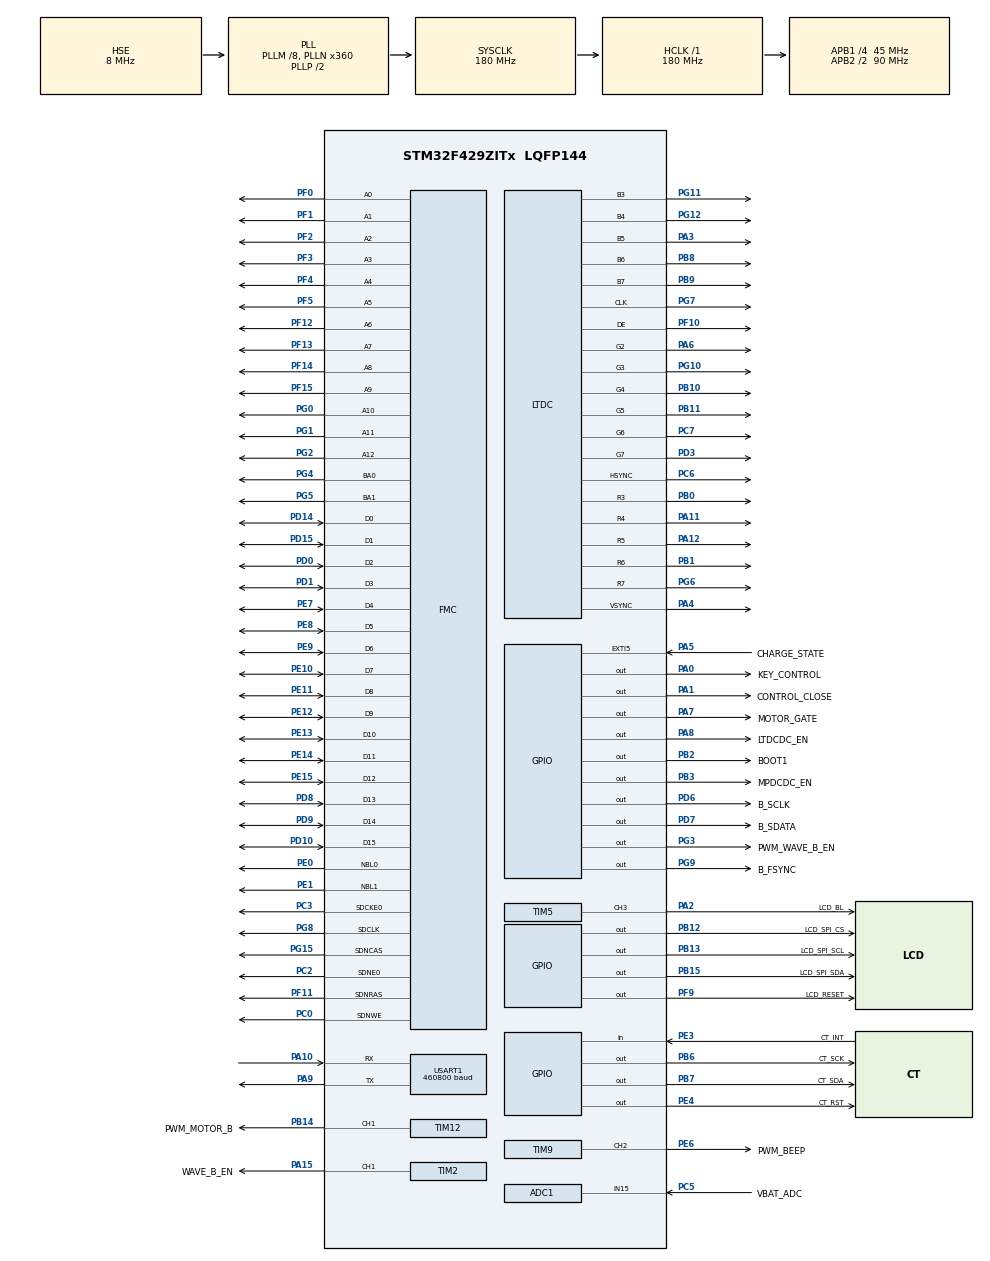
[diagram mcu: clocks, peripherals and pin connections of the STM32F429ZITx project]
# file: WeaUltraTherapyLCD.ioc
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ADC1.Channel-0\#ChannelRegularConversion=ADC_CHANNEL_15
ADC1.NbrOfConversionFlag=1
ADC1.Rank-0\#ChannelRegularConversion=1
ADC1.SamplingTime-0\#ChannelRegularConversion=ADC_SAMPLETIME_3CYCLES
ADC1.master=1
DMA2D.ColorMode=DMA2D_OUTPUT_RGB565
DMA2D.Mode=DMA2D_R2M
Dma.ADC1.0.Direction=DMA_PERIPH_TO_MEMORY
Dma.ADC1.0.FIFOMode=DMA_FIFOMODE_DISABLE
Dma.ADC1.0.Instance=DMA2_Stream0
Dma.ADC1.0.MemDataAlignment=DMA_MDATAALIGN_HALFWORD
Dma.ADC1.0.MemInc=DMA_MINC_ENABLE
Dma.ADC1.0.Mode=DMA_NORMAL
Dma.ADC1.0.PeriphDataAlignment=DMA_PDATAALIGN_HALFWORD
Dma.ADC1.0.PeriphInc=DMA_PINC_DISABLE
Dma.ADC1.0.Priority=DMA_PRIORITY_LOW
Dma.Request0=ADC1
FMC.CASLatency1=FMC_SDRAM_CAS_LATENCY_3
FMC.ColumnBitsNumber1=FMC_SDRAM_COLUMN_BITS_NUM_9
FMC.ExitSelfRefreshDelay1=7
FMC.LoadToActiveDelay1=2
FMC.RCDDelay1=2
FMC.RPDelay1=2
FMC.RPDelay2=2
FMC.ReadBurst1=FMC_SDRAM_RBURST_ENABLE
FMC.ReadBurst2=FMC_SDRAM_RBURST_ENABLE
FMC.ReadPipeDelay1=FMC_SDRAM_RPIPE_DELAY_1
FMC.ReadPipeDelay2=FMC_SDRAM_RPIPE_DELAY_1
FMC.RowCycleDelay1=6
FMC.RowCycleDelay2=6
FMC.SDClockPeriod1=FMC_SDRAM_CLOCK_PERIOD_2
FMC.SDClockPeriod2=FMC_SDRAM_CLOCK_PERIOD_2
FMC.SelfRefreshTime1=6
FMC.WriteRecoveryTime1=4
FREERTOS.Tasks01=ScreenRGB,40,1024,ScreenRGBTask,Default,NULL,Static,ScreenRGBBuffer,ScreenRGBControlBlock;UltraApp,8,256,UltraAppTask,Default,NULL,Static,UltraAppBuffer,UltraAppControlBlock;OtherFunc,8,128,OtherFuncTask,Default,NULL,Static,OtherFuncBuffer,OtherFuncControlBlock
IWDG.Prescaler=IWDG_PRESCALER_32
IWDG.Reload=1000
LTDC.ActiveH=800
LTDC.ActiveW=480
LTDC.Alpha_L0=255
LTDC.BlendingFactor1_L0=LTDC_BLENDING_FACTOR1_PAxCA
LTDC.BlendingFactor2_L0=LTDC_BLENDING_FACTOR2_PAxCA
LTDC.DEPolarity=LTDC_DEPOLARITY_AL
LTDC.FBStartAdress_L0=0xC0000000
LTDC.HBP=30
LTDC.HFP=10
LTDC.HSPolarity=LTDC_HSPOLARITY_AL
LTDC.HSync=2
LTDC.ImageHeight_L0=800
LTDC.ImageWidth_L0=480
LTDC.Layers=0
LTDC.PCPolarity=LTDC_PCPOLARITY_IIPC
LTDC.PixelFormat_L0=LTDC_PIXEL_FORMAT_RGB565
LTDC.VBP=20
LTDC.VFP=80
LTDC.VSPolarity=LTDC_VSPOLARITY_AL
LTDC.VSync=2
LTDC.WindowX1_L0=480
LTDC.WindowY1_L0=800
Mcu.Family=STM32F4
Mcu.Name=STM32F429ZITx
Mcu.Package=LQFP144
NVIC.DMA2_Stream0_IRQn=true\:5\:0\:false\:false\:true\:true\:false\:true\:true
NVIC.EXTI9_5_IRQn=true\:5\:0\:false\:false\:true\:true\:true\:true\:true
NVIC.PriorityGroup=NVIC_PRIORITYGROUP_4
NVIC.TIM2_IRQn=true\:5\:0\:false\:false\:true\:false\:true\:true\:true
NVIC.TIM3_IRQn=true\:5\:0\:false\:false\:true\:true\:true\:true\:true
NVIC.TIM8_BRK_TIM12_IRQn=true\:5\:0\:true\:false\:true\:false\:true\:true\:true
NVIC.TIM8_TRG_COM_TIM14_IRQn=true\:15\:0\:false\:false\:true\:false\:false\:true\:true
NVIC.TIM8_UP_TIM13_IRQn=true\:5\:0\:false\:false\:true\:true\:true\:true\:true
NVIC.TimeBase=TIM8_TRG_COM_TIM14_IRQn
NVIC.TimeBaseIP=TIM14
PA0/WKUP.GPIO_Label=KEY_CONTROL
PA0/WKUP.Signal=GPIO_Output
PA1.GPIO_Label=CONTROL_CLOSE
PA1.Signal=GPIO_Output
PA10.Mode=Asynchronous
PA10.Signal=USART1_RX
PA11.GPIO_Speed=GPIO_SPEED_FREQ_VERY_HIGH
PA11.Mode=RGB565
PA11.Signal=LTDC_R4
PA12.GPIO_Speed=GPIO_SPEED_FREQ_VERY_HIGH
PA12.Mode=RGB565
PA12.Signal=LTDC_R5
PA13.Mode=Serial_Wire
PA13.Signal=SYS_JTMS-SWDIO
PA14.Mode=Serial_Wire
PA14.Signal=SYS_JTCK-SWCLK
PA15.GPIO_Label=WAVE_B_EN
PA15.Signal=S_TIM2_CH1_ETR
PA2.GPIO_Label=LCD_BL
PA2.Signal=S_TIM5_CH3
PA3.GPIO_Speed=GPIO_SPEED_FREQ_VERY_HIGH
PA3.Mode=RGB565
PA3.Signal=LTDC_B5
PA4.GPIO_Speed=GPIO_SPEED_FREQ_VERY_HIGH
PA4.Mode=RGB565
PA4.Signal=LTDC_VSYNC
PA5.GPIO_Label=CHARGE_STATE
PA5.GPIO_ModeDefaultEXTI=GPIO_MODE_IT_RISING_FALLING
PA5.GPIO_PuPd=GPIO_PULLUP
PA5.Signal=GPXTI5
PA6.GPIO_Speed=GPIO_SPEED_FREQ_VERY_HIGH
PA6.Mode=RGB565
PA6.Signal=LTDC_G2
PA7.GPIO_Label=MOTOR_GATE
PA7.GPIO_ModeDefaultOutputPP=GPIO_MODE_OUTPUT_PP
PA7.GPIO_PuPd=GPIO_PULLUP
PA7.GPIO_Speed=GPIO_SPEED_FREQ_HIGH
PA7.PinState=GPIO_PIN_RESET
PA7.Signal=GPIO_Output
PA8.GPIO_Label=LTDCDC_EN
PA8.Signal=GPIO_Output
PA9.Mode=Asynchronous
PA9.Signal=USART1_TX
PB0.GPIO_Speed=GPIO_SPEED_FREQ_VERY_HIGH
PB0.Mode=RGB565
PB0.Signal=LTDC_R3
PB1.GPIO_Speed=GPIO_SPEED_FREQ_VERY_HIGH
PB1.Mode=RGB565
PB1.Signal=LTDC_R6
PB10.GPIO_Speed=GPIO_SPEED_FREQ_VERY_HIGH
PB10.Mode=RGB565
PB10.Signal=LTDC_G4
PB11.GPIO_Speed=GPIO_SPEED_FREQ_VERY_HIGH
PB11.Mode=RGB565
PB11.Signal=LTDC_G5
PB12.GPIO_Label=LCD_SPI_CS
PB12.GPIO_PuPd=GPIO_PULLUP
PB12.GPIO_Speed=GPIO_SPEED_FREQ_VERY_HIGH
PB12.PinState=GPIO_PIN_RESET
PB12.Signal=GPIO_Output
PB13.GPIO_Label=LCD_SPI_SCL
PB13.GPIO_PuPd=GPIO_PULLUP
PB13.GPIO_Speed=GPIO_SPEED_FREQ_VERY_HIGH
PB13.Signal=GPIO_Output
PB14.GPIO_Label=PWM_MOTOR_B
PB14.Signal=S_TIM12_CH1
PB15.GPIO_Label=LCD_SPI_SDA
PB15.GPIO_PuPd=GPIO_PULLUP
PB15.GPIO_Speed=GPIO_SPEED_FREQ_VERY_HIGH
PB15.Signal=GPIO_Output
PB2/BOOT1.GPIO_Label=BOOT1
PB2/BOOT1.GPIO_PuPd=GPIO_PULLDOWN
PB2/BOOT1.Signal=GPIO_Output
PB3.GPIO_Label=MPDCDC_EN
PB3.Signal=GPIO_Output
PB6.GPIO_Label=CT_SCK
PB6.GPIO_ModeDefaultOutputPP=GPIO_MODE_OUTPUT_OD
PB6.GPIO_PuPd=GPIO_PULLUP
PB6.GPIO_Speed=GPIO_SPEED_FREQ_VERY_HIGH
PB6.Signal=GPIO_Output
PB7.GPIO_Label=CT_SDA
PB7.GPIO_ModeDefaultOutputPP=GPIO_MODE_OUTPUT_OD
PB7.GPIO_PuPd=GPIO_PULLUP
PB7.GPIO_Speed=GPIO_SPEED_FREQ_VERY_HIGH
PB7.Signal=GPIO_Output
PB8.GPIO_Speed=GPIO_SPEED_FREQ_VERY_HIGH
PB8.Mode=RGB565
PB8.Signal=LTDC_B6
PB9.GPIO_Speed=GPIO_SPEED_FREQ_VERY_HIGH
PB9.Mode=RGB565
PB9.Signal=LTDC_B7
PC0.Signal=FMC_SDNWE
PC2.Mode=SdramChipSelect1_1
PC2.Signal=FMC_SDNE0
PC3.Mode=SdramChipSelect1_1
PC3.Signal=FMC_SDCKE0
PC5.GPIO_Label=VBAT_ADC
PC5.Signal=ADCx_IN15
PC6.GPIO_Speed=GPIO_SPEED_FREQ_VERY_HIGH
PC6.Mode=RGB565
PC6.Signal=LTDC_HSYNC
PC7.GPIO_Speed=GPIO_SPEED_FREQ_VERY_HIGH
PC7.Mode=RGB565
PC7.Signal=LTDC_G6
PD0.Signal=FMC_D2_DA2
PD1.Signal=FMC_D3_DA3
PD10.Signal=FMC_D15_DA15
PD14.Signal=FMC_D0_DA0
PD15.Signal=FMC_D1_DA1
PD3.GPIO_Speed=GPIO_SPEED_FREQ_VERY_HIGH
PD3.Mode=RGB565
PD3.Signal=LTDC_G7
PD6.GPIO_Label=B_SCLK
PD6.GPIO_Speed=GPIO_SPEED_FREQ_VERY_HIGH
PD6.Signal=GPIO_Output
PD7.GPIO_Label=B_SDATA
PD7.GPIO_Speed=GPIO_SPEED_FREQ_VERY_HIGH
PD7.Signal=GPIO_Output
PD8.Signal=FMC_D13_DA13
PD9.Signal=FMC_D14_DA14
PE0.Signal=FMC_NBL0
PE1.Signal=FMC_NBL1
PE10.Signal=FMC_D7_DA7
PE11.Signal=FMC_D8_DA8
PE12.Signal=FMC_D9_DA9
PE13.Signal=FMC_D10_DA10
PE14.Signal=FMC_D11_DA11
PE15.Signal=FMC_D12_DA12
PE3.GPIO_Label=CT_INT
PE3.GPIO_Mode=GPIO_MODE_INPUT
PE3.GPIO_PuPd=GPIO_PULLUP
PE3.Signal=GPIO_Input
PE4.GPIO_Label=CT_RST
PE4.Signal=GPIO_Output
PE6.GPIO_Label=PWM_BEEP
PE6.Signal=S_TIM9_CH2
PE7.Signal=FMC_D4_DA4
PE8.Signal=FMC_D5_DA5
PE9.Signal=FMC_D6_DA6
PF0.Signal=FMC_A0
PF1.Signal=FMC_A1
PF10.GPIO_Speed=GPIO_SPEED_FREQ_VERY_HIGH
PF10.Mode=RGB565
PF10.Signal=LTDC_DE
PF11.Signal=FMC_SDNRAS
PF12.Signal=FMC_A6
PF13.Signal=FMC_A7
PF14.Signal=FMC_A8
PF15.Signal=FMC_A9
PF2.Signal=FMC_A2
PF3.Signal=FMC_A3
PF4.Signal=FMC_A4
PF5.Signal=FMC_A5
PF9.GPIO_Label=LCD_RESET
PF9.Signal=GPIO_Output
PG0.Signal=FMC_A10
PG1.Signal=FMC_A11
PG10.GPIO_Speed=GPIO_SPEED_FREQ_VERY_HIGH
PG10.Mode=RGB565
PG10.Signal=LTDC_G3
PG11.GPIO_Speed=GPIO_SPEED_FREQ_VERY_HIGH
PG11.Mode=RGB565
PG11.Signal=LTDC_B3
PG12.GPIO_Speed=GPIO_SPEED_FREQ_VERY_HIGH
PG12.Mode=RGB565
PG12.Signal=LTDC_B4
PG15.Signal=FMC_SDNCAS
PG2.Signal=FMC_A12
PG3.GPIO_Label=PWM_WAVE_B_EN
PG3.Signal=GPIO_Output
PG4.Signal=FMC_A14_BA0
PG5.Signal=FMC_A15_BA1
PG6.GPIO_Speed=GPIO_SPEED_FREQ_VERY_HIGH
PG6.Mode=RGB565
PG6.Signal=LTDC_R7
PG7.GPIO_Speed=GPIO_SPEED_FREQ_VERY_HIGH
PG7.Mode=RGB565
PG7.Signal=LTDC_CLK
PG8.Signal=FMC_SDCLK
PG9.GPIO_Label=B_FSYNC
PG9.GPIO_Speed=GPIO_SPEED_FREQ_LOW
PG9.Signal=GPIO_Output
PH0/OSC_IN.Mode=HSE-External-Oscillator
PH0/OSC_IN.Signal=RCC_OSC_IN
PH1/OSC_OUT.Mode=HSE-External-Oscillator
PH1/OSC_OUT.Signal=RCC_OSC_OUT
ProjectManager.HeapSize=0x200
ProjectManager.StackSize=0x400
ProjectManager.TargetToolchain=MDK-ARM V5.32
RCC.48MHZClocksFreq_Value=90000000
RCC.AHBFreq_Value=180000000
RCC.APB1CLKDivider=RCC_HCLK_DIV4
RCC.APB1Freq_Value=45000000
RCC.APB1TimFreq_Value=90000000
RCC.APB2CLKDivider=RCC_HCLK_DIV2
RCC.APB2Freq_Value=90000000
RCC.APB2TimFreq_Value=180000000
RCC.CortexFreq_Value=180000000
RCC.HCLKFreq_Value=180000000
RCC.HSE_VALUE=8000000
RCC.HSI_VALUE=16000000
RCC.LSE_VALUE=32768
RCC.PLLM=8
RCC.PLLN=360
RCC.PLLSAIDivR=RCC_PLLSAIDIVR_4
RCC.PLLSAIN=336
RCC.PLLSAIR=3
RCC.PLLSourceVirtual=RCC_PLLSOURCE_HSE
RCC.SYSCLKFreq_VALUE=180000000
RCC.SYSCLKSource=RCC_SYSCLKSOURCE_PLLCLK
RCC.VCOOutputFreq_Value=360000000
SH.ADCx_IN15.0=ADC1_IN15,IN15
SH.FMC_A0.0=FMC_A0,13b-sda1
SH.FMC_A1.0=FMC_A1,13b-sda1
SH.FMC_A10.0=FMC_A10,13b-sda1
SH.FMC_A11.0=FMC_A11,13b-sda1
SH.FMC_A12.0=FMC_A12,13b-sda1
SH.FMC_A14_BA0.0=FMC_BA0,FourSdramBanks1
SH.FMC_A15_BA1.0=FMC_BA1,FourSdramBanks1
SH.FMC_A2.0=FMC_A2,13b-sda1
SH.FMC_A3.0=FMC_A3,13b-sda1
SH.FMC_A4.0=FMC_A4,13b-sda1
SH.FMC_A5.0=FMC_A5,13b-sda1
SH.FMC_A6.0=FMC_A6,13b-sda1
SH.FMC_A7.0=FMC_A7,13b-sda1
SH.FMC_A8.0=FMC_A8,13b-sda1
SH.FMC_A9.0=FMC_A9,13b-sda1
SH.FMC_D0_DA0.0=FMC_D0,sd-16b-d1
SH.FMC_D10_DA10.0=FMC_D10,sd-16b-d1
SH.FMC_D11_DA11.0=FMC_D11,sd-16b-d1
SH.FMC_D12_DA12.0=FMC_D12,sd-16b-d1
SH.FMC_D13_DA13.0=FMC_D13,sd-16b-d1
SH.FMC_D14_DA14.0=FMC_D14,sd-16b-d1
SH.FMC_D15_DA15.0=FMC_D15,sd-16b-d1
SH.FMC_D1_DA1.0=FMC_D1,sd-16b-d1
SH.FMC_D2_DA2.0=FMC_D2,sd-16b-d1
SH.FMC_D3_DA3.0=FMC_D3,sd-16b-d1
SH.FMC_D4_DA4.0=FMC_D4,sd-16b-d1
SH.FMC_D5_DA5.0=FMC_D5,sd-16b-d1
SH.FMC_D6_DA6.0=FMC_D6,sd-16b-d1
SH.FMC_D7_DA7.0=FMC_D7,sd-16b-d1
SH.FMC_D8_DA8.0=FMC_D8,sd-16b-d1
SH.FMC_D9_DA9.0=FMC_D9,sd-16b-d1
SH.FMC_NBL0.0=FMC_NBL0,Sd2ByteEnable1
SH.FMC_NBL1.0=FMC_NBL1,Sd2ByteEnable1
SH.FMC_SDCLK.0=FMC_SDCLK,13b-sda1
SH.FMC_SDNCAS.0=FMC_SDNCAS,13b-sda1
SH.FMC_SDNRAS.0=FMC_SDNRAS,13b-sda1
SH.FMC_SDNWE.0=FMC_SDNWE,13b-sda1
SH.S_TIM12_CH1.0=TIM12_CH1,PWM Generation1 CH1
SH.S_TIM2_CH1_ETR.0=TIM2_CH1,PWM Generation1 CH1
SH.S_TIM5_CH3.0=TIM5_CH3,PWM Generation3 CH3
SH.S_TIM9_CH2.0=TIM9_CH2,PWM Generation2 CH2
TIM12.Channel-PWM\ Generation1\ CH1=TIM_CHANNEL_1
TIM12.Period=4256-1
TIM12.Prescaler=90-1
TIM2.Channel-PWM\ Generation1\ CH1=TIM_CHANNEL_1
TIM2.Period=2500
TIM2.Prescaler=90-1
TIM3.Period=100-1
TIM3.Prescaler=90-1
TIM5.Channel-PWM\ Generation3\ CH3=TIM_CHANNEL_3
TIM5.Period=4255
TIM5.Prescaler=90-1
TIM8.Period=1000
TIM8.Prescaler=180-1
TIM9.Channel-PWM\ Generation2\ CH2=TIM_CHANNEL_2
TIM9.Period=400
TIM9.Prescaler=180-1
USART1.BaudRate=460800
USART1.VirtualMode=VM_ASYNC
VP_DMA2D_VS_DMA2D.Mode=DMA2D_Activate
VP_FREERTOS_VS_CMSIS_V2.Mode=CMSIS_V2
VP_IWDG_VS_IWDG.Mode=IWDG_Activate
VP_SYS_VS_tim14.Mode=TIM14
VP_TIM12_VS_ClockSourceINT.Mode=Internal
VP_TIM2_VS_ClockSourceINT.Mode=Internal
VP_TIM3_VS_ClockSourceINT.Mode=Internal
VP_TIM5_VS_ClockSourceINT.Mode=Internal
VP_TIM8_VS_ClockSourceINT.Mode=Internal
VP_TIM9_VS_ClockSourceINT.Mode=Internal
board=custom

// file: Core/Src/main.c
/* USER CODE BEGIN Header */
/**
  ******************************************************************************
  * @file           : main.c
  * @brief          : Main program body
  ******************************************************************************
  * @attention
  *
  * Copyright (c) 2024 STMicroelectronics.
  * All rights reserved.
  *
  * This software is licensed under terms that can be found in the LICENSE file
  * in the root directory of this software component.
  * If no LICENSE file comes with this software, it is provided AS-IS.
  *
  ******************************************************************************
  */
/* USER CODE END Header */
#include "main.h"
#include "cmsis_os.h"
#include "adc.h"
#include "dma.h"
#include "dma2d.h"
#include "iwdg.h"
#include "ltdc.h"
#include "tim.h"
#include "usart.h"
#include "gpio.h"
#include "fmc.h"

/* USER CODE BEGIN Includes */
#include "dev_malloc.h"
#include "lv_port_disp_template.h"
#include "lv_port_indev_template.h"
#include "dev_st7701.h"
#include "dev_app.h"
#include "lv_mainstart.h"
/* USER CODE END Includes */

/* USER CODE BEGIN PV */
uint32_t ScreenTime = 0;										//屝幕主界面数杮刷新时�?
uint32_t StandyTime = 0;										//待机时间
uint32_t ChargeRecvTime = 0;								//充电接收时间
uint32_t BatteryTime = 0;										//主界面电池刷新时�?
uint32_t BackLedTime = 0;			  						//背光启动时间
uint32_t PowerOnTime = 0;										//正式�?机时�?
uint32_t Charge_Time = 0;										//充电时长
uint32_t ShuntDownCount = 0;
uint32_t MotorTime = 0;
uint8_t CompleteFlg = 0;										//启动成功
uint32_t UltraWorkTim = 0;
uint32_t UnlockCount = 0;
uint32_t VibraFeedBackTime = 0;												//震动反馈时间
uint32_t DisplayTime = 0;
uint32_t BeatTime = 0;
uint32_t HintTime = 0;
uint8_t LongPressFlg = 0;
uint32_t LongPressTime = 0;
/* USER CODE END PV */

void SystemClock_Config(void);
void MX_FREERTOS_Init(void);

int main(void)
{

  /* MCU Configuration--------------------------------------------------------*/

  /* Reset of all peripherals, Initializes the Flash interface and the Systick. */
  HAL_Init();

  /* Configure the system clock */
  SystemClock_Config();

  /* Initialize all configured peripherals */
  MX_GPIO_Init();
  MX_DMA_Init();
  MX_DMA2D_Init();
  MX_FMC_Init();
  MX_TIM2_Init();
  MX_LTDC_Init();
  MX_ADC1_Init();
  MX_TIM5_Init();
  MX_TIM9_Init();
  MX_TIM3_Init();
  MX_TIM12_Init();
  MX_TIM8_Init();
  MX_USART1_UART_Init();
  //MX_IWDG_Init();
  /* USER CODE BEGIN 2 */
	UltraParam_Init();
	st7701_init();
	my_mem_init(SRAMIN);                        				/* 初始化内部SRAM内存�? */
	my_mem_init(SRAMEX);                        				/* 初始化外部SRAM内存�? */
	lv_init();                                          /* lvgl系统初始�? */
	lv_port_disp_init();                                /* lvgl显示接口初始�?,放在lv_init()的后�?*/
	lv_port_indev_init();                               /* lvgl输入接口初始�?,放在lv_init()的后�?*/

	HAL_TIM_Base_Start(&htim2);
	HAL_TIM_Base_Start(&htim5);
	HAL_TIM_Base_Start(&htim9);
	HAL_TIM_Base_Start(&htim12);
	HAL_TIM_Base_Start_IT(&htim3);
	HAL_TIM_Base_Start_IT(&htim8);

  HAL_TIM_PWM_Start(&htim2,TIM_CHANNEL_1);
	HAL_TIM_PWM_Start(&htim5,TIM_CHANNEL_3);
	HAL_TIM_PWM_Start(&htim9,TIM_CHANNEL_2);
	HAL_TIM_PWM_Start(&htim12,TIM_CHANNEL_1);
  /* USER CODE END 2 */

  /* Init scheduler */
  osKernelInitialize();

  /* Call init function for freertos objects (in cmsis_os2.c) */
  MX_FREERTOS_Init();

  /* Start scheduler */
  osKernelStart();

  /* We should never get here as control is now taken by the scheduler */

  /* Infinite loop */
  while (1)
  {

  }
}

void SystemClock_Config(void)
{
  RCC_OscInitTypeDef RCC_OscInitStruct = {0};
  RCC_ClkInitTypeDef RCC_ClkInitStruct = {0};

  /** Configure the main internal regulator output voltage
  */
  __HAL_RCC_PWR_CLK_ENABLE();
  __HAL_PWR_VOLTAGESCALING_CONFIG(PWR_REGULATOR_VOLTAGE_SCALE1);

  /** Initializes the RCC Oscillators according to the specified parameters
  * in the RCC_OscInitTypeDef structure.
  */
  RCC_OscInitStruct.OscillatorType = RCC_OSCILLATORTYPE_LSI|RCC_OSCILLATORTYPE_HSE;
  RCC_OscInitStruct.HSEState = RCC_HSE_ON;
  RCC_OscInitStruct.LSIState = RCC_LSI_ON;
  RCC_OscInitStruct.PLL.PLLState = RCC_PLL_ON;
  RCC_OscInitStruct.PLL.PLLSource = RCC_PLLSOURCE_HSE;
  RCC_OscInitStruct.PLL.PLLM = 8;
  RCC_OscInitStruct.PLL.PLLN = 360;
  RCC_OscInitStruct.PLL.PLLP = RCC_PLLP_DIV2;
  RCC_OscInitStruct.PLL.PLLQ = 4;
  if (HAL_RCC_OscConfig(&RCC_OscInitStruct) != HAL_OK)
  {
    Error_Handler();
  }

  /** Activate the Over-Drive mode
  */
  if (HAL_PWREx_EnableOverDrive() != HAL_OK)
  {
    Error_Handler();
  }

  /** Initializes the CPU, AHB and APB buses clocks
  */
  RCC_ClkInitStruct.ClockType = RCC_CLOCKTYPE_HCLK|RCC_CLOCKTYPE_SYSCLK
                              |RCC_CLOCKTYPE_PCLK1|RCC_CLOCKTYPE_PCLK2;
  RCC_ClkInitStruct.SYSCLKSource = RCC_SYSCLKSOURCE_PLLCLK;
  RCC_ClkInitStruct.AHBCLKDivider = RCC_SYSCLK_DIV1;
  RCC_ClkInitStruct.APB1CLKDivider = RCC_HCLK_DIV4;
  RCC_ClkInitStruct.APB2CLKDivider = RCC_HCLK_DIV2;

  if (HAL_RCC_ClockConfig(&RCC_ClkInitStruct, FLASH_LATENCY_5) != HAL_OK)
  {
    Error_Handler();
  }
}

void HAL_TIM_PeriodElapsedCallback(TIM_HandleTypeDef *htim)
{
  /* USER CODE BEGIN Callback 0 */
	static uint8_t BeepTime = 0;

  /* USER CODE END Callback 0 */
  if (htim->Instance == TIM14) {
    HAL_IncTick();
  }
  /* USER CODE BEGIN Callback 1 */
	//1ms周期
	if(htim->Instance == TIM8)
	{
		  BackLedTime++;
		  StandyTime++;
			ScreenTime++;
		  BatteryTime++;
			PowerOnTime++;
			MotorTime++;
			ShuntDownCount++;
			UltraWorkTim++;
			UnlockCount++;
      VibraFeedBackTime++;
      BeatTime++;

			if((ScreenState == STOP) || (ScreenState == COMPLETE))
			{
					HintTime++;
			}else
			{
				  HintTime = 0;
			}

      if (DisplayFlg == 1)
      {
         DisplayTime++;
      }

			if(PowerOnTime > 1500)
			{
					CompleteFlg = 1;
			}

			if(LongPressFlg == 1)
			{
				LongPressTime++;
			}else
			{
				LongPressTime = 0;
			}

			BeepTime++;
			if(BeepTime > 8)
			{
					Beep_MainFunc();
					BeepTime = 0;
			}

			if(DevWorkState == CHARGE_STATE)
			{
				Charge_Time++;
			}
	}

	if(htim->Instance == TIM3)
	{
			ChargeRecvTime++;
	}
  /* USER CODE END Callback 1 */
}

void Error_Handler(void)
{
  __disable_irq();
  while (1)
  {
  }
}

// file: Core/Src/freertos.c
/* USER CODE BEGIN Header */
/**
  ******************************************************************************
  * File Name          : freertos.c
  * Description        : Code for freertos applications
  ******************************************************************************
  * @attention
  *
  * Copyright (c) 2024 STMicroelectronics.
  * All rights reserved.
  *
  * This software is licensed under terms that can be found in the LICENSE file
  * in the root directory of this software component.
  * If no LICENSE file comes with this software, it is provided AS-IS.
  *
  ******************************************************************************
  */
/* USER CODE END Header */

#include "FreeRTOS.h"
#include "task.h"
#include "main.h"
#include "cmsis_os.h"

/* USER CODE BEGIN Includes */
#include "lv_mainstart.h"
#include "lvgl.h"
#include "dev_gt911.h"
#include "dev_ltdc.h"
#include "dev_beep.h"
#include "custom.h"
#include "tim.h"
#include "dev_app.h"
/* USER CODE END Includes */

typedef StaticTask_t osStaticThreadDef_t;

/* USER CODE BEGIN Variables */
extern IWDG_HandleTypeDef hiwdg;
extern uint16_t RefreshCount;
extern uint32_t BackLedTime;
static uint8_t StartFlg = 0;

/* USER CODE END Variables */
/* Definitions for ScreenRGB */
osThreadId_t ScreenRGBHandle;
uint32_t ScreenRGBBuffer[ 1024 ];
osStaticThreadDef_t ScreenRGBControlBlock;
const osThreadAttr_t ScreenRGB_attributes = {
  .name = "ScreenRGB",
  .cb_mem = &ScreenRGBControlBlock,
  .cb_size = sizeof(ScreenRGBControlBlock),
  .stack_mem = &ScreenRGBBuffer[0],
  .stack_size = sizeof(ScreenRGBBuffer),
  .priority = (osPriority_t) osPriorityHigh,
};
/* Definitions for UltraApp */
osThreadId_t UltraAppHandle;
uint32_t UltraAppBuffer[ 256 ];
osStaticThreadDef_t UltraAppControlBlock;
const osThreadAttr_t UltraApp_attributes = {
  .name = "UltraApp",
  .cb_mem = &UltraAppControlBlock,
  .cb_size = sizeof(UltraAppControlBlock),
  .stack_mem = &UltraAppBuffer[0],
  .stack_size = sizeof(UltraAppBuffer),
  .priority = (osPriority_t) osPriorityLow,
};
/* Definitions for OtherFunc */
osThreadId_t OtherFuncHandle;
uint32_t OtherFuncBuffer[ 128 ];
osStaticThreadDef_t OtherFuncControlBlock;
const osThreadAttr_t OtherFunc_attributes = {
  .name = "OtherFunc",
  .cb_mem = &OtherFuncControlBlock,
  .cb_size = sizeof(OtherFuncControlBlock),
  .stack_mem = &OtherFuncBuffer[0],
  .stack_size = sizeof(OtherFuncBuffer),
  .priority = (osPriority_t) osPriorityLow,
};

void ScreenRGBTask(void *argument);
void UltraAppTask(void *argument);
void OtherFuncTask(void *argument);

void MX_FREERTOS_Init(void); /* (MISRA C 2004 rule 8.1) */

void MX_FREERTOS_Init(void) {

  /* Create the thread(s) */
  /* creation of ScreenRGB */
  ScreenRGBHandle = osThreadNew(ScreenRGBTask, NULL, &ScreenRGB_attributes);

  /* creation of UltraApp */
  UltraAppHandle = osThreadNew(UltraAppTask, NULL, &UltraApp_attributes);

  /* creation of OtherFunc */
  OtherFuncHandle = osThreadNew(OtherFuncTask, NULL, &OtherFunc_attributes);

}

void ScreenRGBTask(void *argument)
{
  /* USER CODE BEGIN ScreenRGBTask */
	static uint8_t PagingFLg = 0;
	uint16_t tempval = 0;
	lv_mainstart();
  /* Infinite loop */
  for(;;)
  {
		if(StartFlg == 0)
		{
			  tempval = LightLevel * 43;

				if(BatteryState == CHARGE)
				{
						if(PagingFLg == 0)
						{
							ui_load_scr_animation(&guider_ui, &guider_ui.charge, guider_ui.charge_del, &guider_ui.boot_del, setup_scr_charge, LV_SCR_LOAD_ANIM_NONE, 100, 100, false, true);
							PagingFLg = 1;
						}else
						{
							  RefreshCount = 120;
								Screen_Id = CHAREG_SCREEN;
								ChargeBatLevelInit();
						}

						if(BackLedTime >= 1500)
						{
							__HAL_TIM_SetCompare(LCDBL_HANDLE,LCDBL_CHANNLE,tempval);
							StartFlg = 1;
						}
				}else
				{
						if(BackLedTime >= 1500)
						{
							__HAL_TIM_SetCompare(LCDBL_HANDLE,LCDBL_CHANNLE,tempval);
						}
						if(BackLedTime >= 3500)
						{
								ui_load_scr_animation(&guider_ui, &guider_ui.main, guider_ui.main_del, &guider_ui.boot_del, setup_scr_main, LV_SCR_LOAD_ANIM_FADE_ON, 0, 50, false, true);
								StartFlg = 1;
						}
				}
		}else if(StartFlg == 1)
		{
				ScreenFunc();
		}

		lv_timer_handler();
    osDelay(5);
  }
  /* USER CODE END ScreenRGBTask */
}

void UltraAppTask(void *argument)
{
  /* USER CODE BEGIN UltraAppTask */
	static uint8_t BatLevelInitFlg = 0;
	DevSystem_Init();
	DevAdc_Init();
  /* Infinite loop */
  for(;;)
  {
		DevMPC5043_MainFunc();
		DevAdc_MainFunc();

    if(StartFlg == 1)
    {
      DevAPP_MainFunc();
      UltraParam_Set();
    }
    osDelay(10);
  }
  /* USER CODE END UltraAppTask */
}

void OtherFuncTask(void *argument)
{
  /* USER CODE BEGIN OtherFuncTask */

  /* Infinite loop */
  for(;;)
  {
    if(StartFlg == 1)
    {
			Screen_TriggerFunc();
    }
    osDelay(100);
  }
  /* USER CODE END OtherFuncTask */
}
